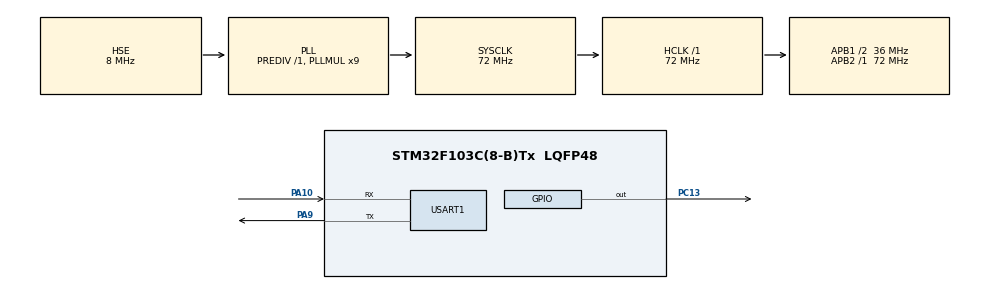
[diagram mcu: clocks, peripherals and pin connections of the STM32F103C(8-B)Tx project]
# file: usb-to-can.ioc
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Dma.Request0=USART1_RX
Dma.Request1=USART1_TX
Dma.USART1_RX.0.Direction=DMA_PERIPH_TO_MEMORY
Dma.USART1_RX.0.Instance=DMA1_Channel5
Dma.USART1_RX.0.MemDataAlignment=DMA_MDATAALIGN_BYTE
Dma.USART1_RX.0.MemInc=DMA_MINC_ENABLE
Dma.USART1_RX.0.Mode=DMA_CIRCULAR
Dma.USART1_RX.0.PeriphDataAlignment=DMA_PDATAALIGN_BYTE
Dma.USART1_RX.0.PeriphInc=DMA_PINC_DISABLE
Dma.USART1_RX.0.Priority=DMA_PRIORITY_LOW
Dma.USART1_TX.1.Direction=DMA_MEMORY_TO_PERIPH
Dma.USART1_TX.1.Instance=DMA1_Channel4
Dma.USART1_TX.1.MemDataAlignment=DMA_MDATAALIGN_BYTE
Dma.USART1_TX.1.MemInc=DMA_MINC_ENABLE
Dma.USART1_TX.1.Mode=DMA_NORMAL
Dma.USART1_TX.1.PeriphDataAlignment=DMA_PDATAALIGN_BYTE
Dma.USART1_TX.1.PeriphInc=DMA_PINC_DISABLE
Dma.USART1_TX.1.Priority=DMA_PRIORITY_LOW
Mcu.Family=STM32F1
Mcu.Name=STM32F103C(8-B)Tx
Mcu.Package=LQFP48
NVIC.DMA1_Channel4_IRQn=true\:0\:0\:false\:false\:true\:false
NVIC.DMA1_Channel5_IRQn=true\:0\:0\:false\:false\:true\:false
NVIC.PriorityGroup=NVIC_PRIORITYGROUP_4
NVIC.USART1_IRQn=true\:0\:0\:false\:false\:true\:true
PA10.Mode=Asynchronous
PA10.Signal=USART1_RX
PA13.Mode=Serial_Wire
PA13.Signal=SYS_JTMS-SWDIO
PA14.Mode=Serial_Wire
PA14.Signal=SYS_JTCK-SWCLK
PA9.Mode=Asynchronous
PA9.Signal=USART1_TX
PC13-TAMPER-RTC.Signal=GPIO_Output
PD0-OSC_IN.Mode=HSE-External-Oscillator
PD0-OSC_IN.Signal=RCC_OSC_IN
PD1-OSC_OUT.Mode=HSE-External-Oscillator
PD1-OSC_OUT.Signal=RCC_OSC_OUT
ProjectManager.HeapSize=0x200
ProjectManager.StackSize=0x400
ProjectManager.TargetToolchain=MDK-ARM V5
RCC.AHBFreq_Value=72000000
RCC.APB1CLKDivider=RCC_HCLK_DIV2
RCC.APB1Freq_Value=36000000
RCC.APB1TimFreq_Value=72000000
RCC.APB2Freq_Value=72000000
RCC.APB2TimFreq_Value=72000000
RCC.HCLKFreq_Value=72000000
RCC.PLLMUL=RCC_PLL_MUL9
RCC.PLLSourceVirtual=RCC_PLLSOURCE_HSE
RCC.SYSCLKFreq_VALUE=72000000
RCC.SYSCLKSource=RCC_SYSCLKSOURCE_PLLCLK
RCC.USBFreq_Value=72000000
USART1.VirtualMode=VM_ASYNC
board=usb-to-can

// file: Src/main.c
/**
  ******************************************************************************
  * File Name          : main.c
  * Description        : Main program body
  ******************************************************************************
  ** This notice applies to any and all portions of this file
  * that are not between comment pairs USER CODE BEGIN and
  * USER CODE END. Other portions of this file, whether
  * inserted by the user or by software development tools
  * are owned by their respective copyright owners.
  *
  * COPYRIGHT(c) 2019 STMicroelectronics
  *
  * Redistribution and use in source and binary forms, with or without modification,
  * are permitted provided that the following conditions are met:
  *   1. Redistributions of source code must retain the above copyright notice,
  *      this list of conditions and the following disclaimer.
  *   2. Redistributions in binary form must reproduce the above copyright notice,
  *      this list of conditions and the following disclaimer in the documentation
  *      and/or other materials provided with the distribution.
  *   3. Neither the name of STMicroelectronics nor the names of its contributors
  *      may be used to endorse or promote products derived from this software
  *      without specific prior written permission.
  *
  * THIS SOFTWARE IS PROVIDED BY THE COPYRIGHT HOLDERS AND CONTRIBUTORS "AS IS"
  * AND ANY EXPRESS OR IMPLIED WARRANTIES, INCLUDING, BUT NOT LIMITED TO, THE
  * IMPLIED WARRANTIES OF MERCHANTABILITY AND FITNESS FOR A PARTICULAR PURPOSE ARE
  * DISCLAIMED. IN NO EVENT SHALL THE COPYRIGHT HOLDER OR CONTRIBUTORS BE LIABLE
  * FOR ANY DIRECT, INDIRECT, INCIDENTAL, SPECIAL, EXEMPLARY, OR CONSEQUENTIAL
  * DAMAGES (INCLUDING, BUT NOT LIMITED TO, PROCUREMENT OF SUBSTITUTE GOODS OR
  * SERVICES; LOSS OF USE, DATA, OR PROFITS; OR BUSINESS INTERRUPTION) HOWEVER
  * CAUSED AND ON ANY THEORY OF LIABILITY, WHETHER IN CONTRACT, STRICT LIABILITY,
  * OR TORT (INCLUDING NEGLIGENCE OR OTHERWISE) ARISING IN ANY WAY OUT OF THE USE
  * OF THIS SOFTWARE, EVEN IF ADVISED OF THE POSSIBILITY OF SUCH DAMAGE.
  *
  ******************************************************************************
  */

#include "main.h"
#include "stm32f1xx_hal.h"

/* USER CODE BEGIN Includes */

#include "stdbool.h"
#include "math.h"
#include "stdlib.h"
#include "stddef.h"
#include "jitbus.h"

/* USER CODE END Includes */

UART_HandleTypeDef huart1;
DMA_HandleTypeDef hdma_usart1_rx;
DMA_HandleTypeDef hdma_usart1_tx;

/* USER CODE BEGIN PV */
/* Private variables ---------------------------------------------------------*/

#define JB_FLOAT_MSG_SIZE 5
#define JB_INT_MSG_SIZE 5
#define JB_BINARY_MSG_SIZE 5

CircularBuffer RX_buffer;

 _JB_FloatCircularBuffer JB_BufferFloat;
 _JB_IntCircularBuffer JB_BufferInt;
 _JB_UInt32CircularBuffer JB_BufferUInt32;

	JB_MsgFloat JB_FloatMessage[JB_FLOAT_MSG_SIZE];
	JB_MsgInt JB_IntMessage[JB_INT_MSG_SIZE];
	JB_MsgBinary JB_BinaryMessage[JB_BINARY_MSG_SIZE];

	int debug = 0;

	#define CAN_BUFFER_SIZE 3
	JB_MsgBinary receiveCAN[CAN_BUFFER_SIZE];

/* USER CODE END PV */

void SystemClock_Config(void);
static void MX_GPIO_Init(void);
static void MX_DMA_Init(void);
static void MX_USART1_UART_Init(void);

/* USER CODE BEGIN PFP */
/* Private function prototypes -----------------------------------------------*/

/* USER CODE END PFP */

int main(void)
{

  /* USER CODE BEGIN 1 */
/*
	maxDataLimit = pow(2,32)-1;
*/
  /* USER CODE END 1 */

  /* MCU Configuration----------------------------------------------------------*/

  /* Reset of all peripherals, Initializes the Flash interface and the Systick. */
  HAL_Init();

  /* Configure the system clock */
  SystemClock_Config();

  /* Initialize all configured peripherals */
  MX_GPIO_Init();
  MX_DMA_Init();
  MX_USART1_UART_Init();

  /* USER CODE BEGIN 2 */
	JB_UART_Init(&huart1);

  /* USER CODE END 2 */

  /* Infinite loop */
  while (1)
  {

  /* USER CODE BEGIN 3 */

		// ====================================================== //

		int32_t data1 = -(pow(2,31)-1);
		uint32_t data2 = (pow(2,32)-1);
		int32_t  data3 = 2147000000;
		int64_t dataOverflow = -(pow(2,36)-1);

		//JB_UART_SendMsgInt(&huart1, 0x9, 53462);

		// ====================================================== //

		//JB_UART_SendMsgFloat(&huart1, 0x9, 1423.8256);

		// ====================================================== //

		receiveCAN[0].id = 0x07;
		receiveCAN[0].dataUInt32 = float2binary(14.34);

		receiveCAN[1].id = 0x98;
		receiveCAN[1].dataUInt32 = debug;
		debug = debug + 1;

		receiveCAN[2].id = 0x09;
		receiveCAN[2].dataUInt32 = 587;

		JB_UART_SendAllBinaryMsgs(&huart1, (JB_MsgBinary*)receiveCAN, CAN_BUFFER_SIZE );

		// ====================================================== //

		int x = 0;

		if(JB_inWaiting() > 0){

					uint16_t N_Float = JB_inWaitingFloat();
					if(N_Float > JB_FLOAT_MSG_SIZE)
									N_Float = JB_FLOAT_MSG_SIZE;

					if(N_Float > 0){

								for (x = 0; x < N_Float; x++){

											JB_FloatMessage[x] = JB_getFloatMsg();

								}
					}

					uint16_t N_Int = JB_inWaitingInt();
					if(N_Int > JB_INT_MSG_SIZE)
									N_Int = JB_INT_MSG_SIZE;

					if(N_Int  > 0){

								for (x = 0; x < N_Int; x++){

										JB_IntMessage[x] = JB_getIntMsg();
								}
					}

					uint16_t N_Binary = JB_inWaitingBinary();
					if(N_Binary > JB_BINARY_MSG_SIZE)					//El numero de mensajes a guardar en el vector no debe ser
									N_Binary = JB_BINARY_MSG_SIZE;		//mayor que su espacio reservado maximo. Si no, se produce error

					if(N_Binary > 0){

								for(x = 0; x < N_Binary; x++){
									//debug = x;
									JB_BinaryMessage[x] = JB_getBinaryMsg();
								}
					}

		}

		// ====================================================== //

		HAL_GPIO_TogglePin(GPIOC, GPIO_PIN_13);
		HAL_Delay(100);

   	// ====================================================== //

  }
  /* USER CODE END 3 */

}

/** System Clock Configuration
*/
void SystemClock_Config(void)
{

  RCC_OscInitTypeDef RCC_OscInitStruct;
  RCC_ClkInitTypeDef RCC_ClkInitStruct;

    /**Initializes the CPU, AHB and APB busses clocks
    */
  RCC_OscInitStruct.OscillatorType = RCC_OSCILLATORTYPE_HSE;
  RCC_OscInitStruct.HSEState = RCC_HSE_ON;
  RCC_OscInitStruct.HSEPredivValue = RCC_HSE_PREDIV_DIV1;
  RCC_OscInitStruct.HSIState = RCC_HSI_ON;
  RCC_OscInitStruct.PLL.PLLState = RCC_PLL_ON;
  RCC_OscInitStruct.PLL.PLLSource = RCC_PLLSOURCE_HSE;
  RCC_OscInitStruct.PLL.PLLMUL = RCC_PLL_MUL9;
  if (HAL_RCC_OscConfig(&RCC_OscInitStruct) != HAL_OK)
  {
    _Error_Handler(__FILE__, __LINE__);
  }

    /**Initializes the CPU, AHB and APB busses clocks
    */
  RCC_ClkInitStruct.ClockType = RCC_CLOCKTYPE_HCLK|RCC_CLOCKTYPE_SYSCLK
                              |RCC_CLOCKTYPE_PCLK1|RCC_CLOCKTYPE_PCLK2;
  RCC_ClkInitStruct.SYSCLKSource = RCC_SYSCLKSOURCE_PLLCLK;
  RCC_ClkInitStruct.AHBCLKDivider = RCC_SYSCLK_DIV1;
  RCC_ClkInitStruct.APB1CLKDivider = RCC_HCLK_DIV2;
  RCC_ClkInitStruct.APB2CLKDivider = RCC_HCLK_DIV1;

  if (HAL_RCC_ClockConfig(&RCC_ClkInitStruct, FLASH_LATENCY_2) != HAL_OK)
  {
    _Error_Handler(__FILE__, __LINE__);
  }

    /**Configure the Systick interrupt time
    */
  HAL_SYSTICK_Config(HAL_RCC_GetHCLKFreq()/1000);

    /**Configure the Systick
    */
  HAL_SYSTICK_CLKSourceConfig(SYSTICK_CLKSOURCE_HCLK);

  /* SysTick_IRQn interrupt configuration */
  HAL_NVIC_SetPriority(SysTick_IRQn, 0, 0);
}

/* USART1 init function */
static void MX_USART1_UART_Init(void)
{

  huart1.Instance = USART1;
  huart1.Init.BaudRate = 2000000;
  huart1.Init.WordLength = UART_WORDLENGTH_8B;
  huart1.Init.StopBits = UART_STOPBITS_1;
  huart1.Init.Parity = UART_PARITY_NONE;
  huart1.Init.Mode = UART_MODE_TX_RX;
  huart1.Init.HwFlowCtl = UART_HWCONTROL_NONE;
  huart1.Init.OverSampling = UART_OVERSAMPLING_16;
  if (HAL_UART_Init(&huart1) != HAL_OK)
  {
    _Error_Handler(__FILE__, __LINE__);
  }

}

static void MX_DMA_Init(void)
{
  /* DMA controller clock enable */
  __HAL_RCC_DMA1_CLK_ENABLE();

  /* DMA interrupt init */
  /* DMA1_Channel4_IRQn interrupt configuration */
  HAL_NVIC_SetPriority(DMA1_Channel4_IRQn, 0, 0);
  HAL_NVIC_EnableIRQ(DMA1_Channel4_IRQn);
  /* DMA1_Channel5_IRQn interrupt configuration */
  HAL_NVIC_SetPriority(DMA1_Channel5_IRQn, 0, 0);
  HAL_NVIC_EnableIRQ(DMA1_Channel5_IRQn);

}

/** Configure pins as
        * Analog
        * Input
        * Output
        * EVENT_OUT
        * EXTI
*/
static void MX_GPIO_Init(void)
{

  GPIO_InitTypeDef GPIO_InitStruct;

  /* GPIO Ports Clock Enable */
  __HAL_RCC_GPIOC_CLK_ENABLE();
  __HAL_RCC_GPIOD_CLK_ENABLE();
  __HAL_RCC_GPIOA_CLK_ENABLE();

  /*Configure GPIO pin Output Level */
  HAL_GPIO_WritePin(GPIOC, GPIO_PIN_13, GPIO_PIN_RESET);

  /*Configure GPIO pin : PC13 */
  GPIO_InitStruct.Pin = GPIO_PIN_13;
  GPIO_InitStruct.Mode = GPIO_MODE_OUTPUT_PP;
  GPIO_InitStruct.Speed = GPIO_SPEED_FREQ_LOW;
  HAL_GPIO_Init(GPIOC, &GPIO_InitStruct);

}

void _Error_Handler(char * file, int line)
{
  while(1)
  {
  }
}

/************************ (C) COPYRIGHT STMicroelectronics *****END OF FILE****/
